# RX64M_ELC_Pilot register map
File version: 1.0
RX64M_ELC_Pilot peripheral registers generated from iodefine.h (pilot).
Registers are 8-bit, read-write, reset 0x0 unless marked. A register's access mark holds for its fields unless they carry their own. Offsets are from the block's base; lines under a group give offsets from that group; [hi:lo] are bit positions; {n}, {i} and the like mark numbered series; 'fields as' and 'values as' point back to an identical list; <NAME> marks a mode.

## Memory map
0x0008B100 ELC size 0x44

## ELC
Base 0x0008B100
0x00 ELCR reset 0x7F
  [7] ELCON
0x01 ELSR0
  [7:0] ELS
0x04 ELSR3
  [7:0] ELS
0x05 ELSR4
  [7:0] ELS
0x08 ELSR7
  [7:0] ELS
{0x1+i} ELSR{i} (i=10..13)
  [7:0] ELS
0x10 ELSR15
  [7:0] ELS
0x11 ELSR16
  [7:0] ELS
{0x1+i} ELSR{i} (i=18..28)
  [7:0] ELS
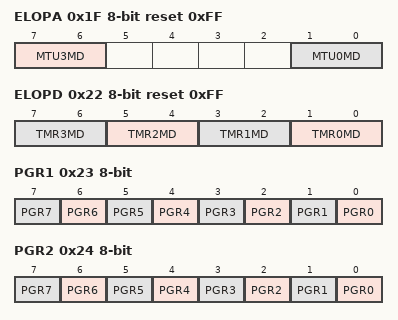
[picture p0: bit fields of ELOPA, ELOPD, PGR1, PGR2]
0x1F ELOPA reset 0xFF
  [7:6] MTU3MD, [1:0] MTU0MD
0x20 ELOPB reset 0xFF
  [1:0] MTU4MD
0x21 ELOPC reset 0xFF
  [3:2] CMT1MD
0x22 ELOPD reset 0xFF
  [2n+1:2n] TMR{n}MD (n=0..3)
0x23 PGR1
  [n] PGR{n} (n=0..7)
0x24 PGR2
  [n] PGR{n} (n=0..7)
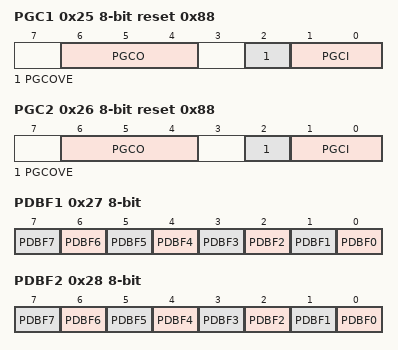
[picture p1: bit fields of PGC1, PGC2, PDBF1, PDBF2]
0x25 PGC1 reset 0x88
  [6:4] PGCO, [2] PGCOVE, [1:0] PGCI
0x26 PGC2 reset 0x88
  [6:4] PGCO, [2] PGCOVE, [1:0] PGCI
0x27 PDBF1
  [n] PDBF{n} (n=0..7)
0x28 PDBF2
  [n] PDBF{n} (n=0..7)
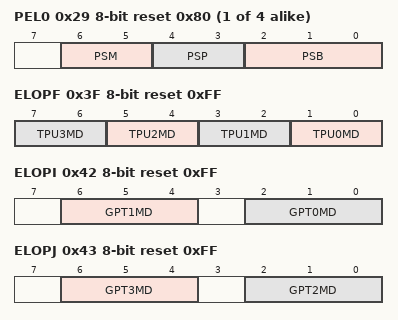
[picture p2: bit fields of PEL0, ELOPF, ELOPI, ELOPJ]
{0x29+i} PEL{i} reset 0x80 (i=0..3)
  [6:5] PSM, [4:3] PSP, [2:0] PSB
0x2D ELSEGR reset 0xBE
0x31 ELSR33
  [7:0] ELS
{0x10+i} ELSR{i} (i=35..38)
  [7:0] ELS
{0x10+i} ELSR{i} (i=41..45)
  [7:0] ELS
0x3F ELOPF reset 0xFF
  [2n+1:2n] TPU{n}MD (n=0..3)
0x41 ELOPH reset 0xFF
  [1:0] CMTW0MD
0x42 ELOPI reset 0xFF
  [6:4] GPT1MD, [2:0] GPT0MD
0x43 ELOPJ reset 0xFF
  [6:4] GPT3MD, [2:0] GPT2MD
